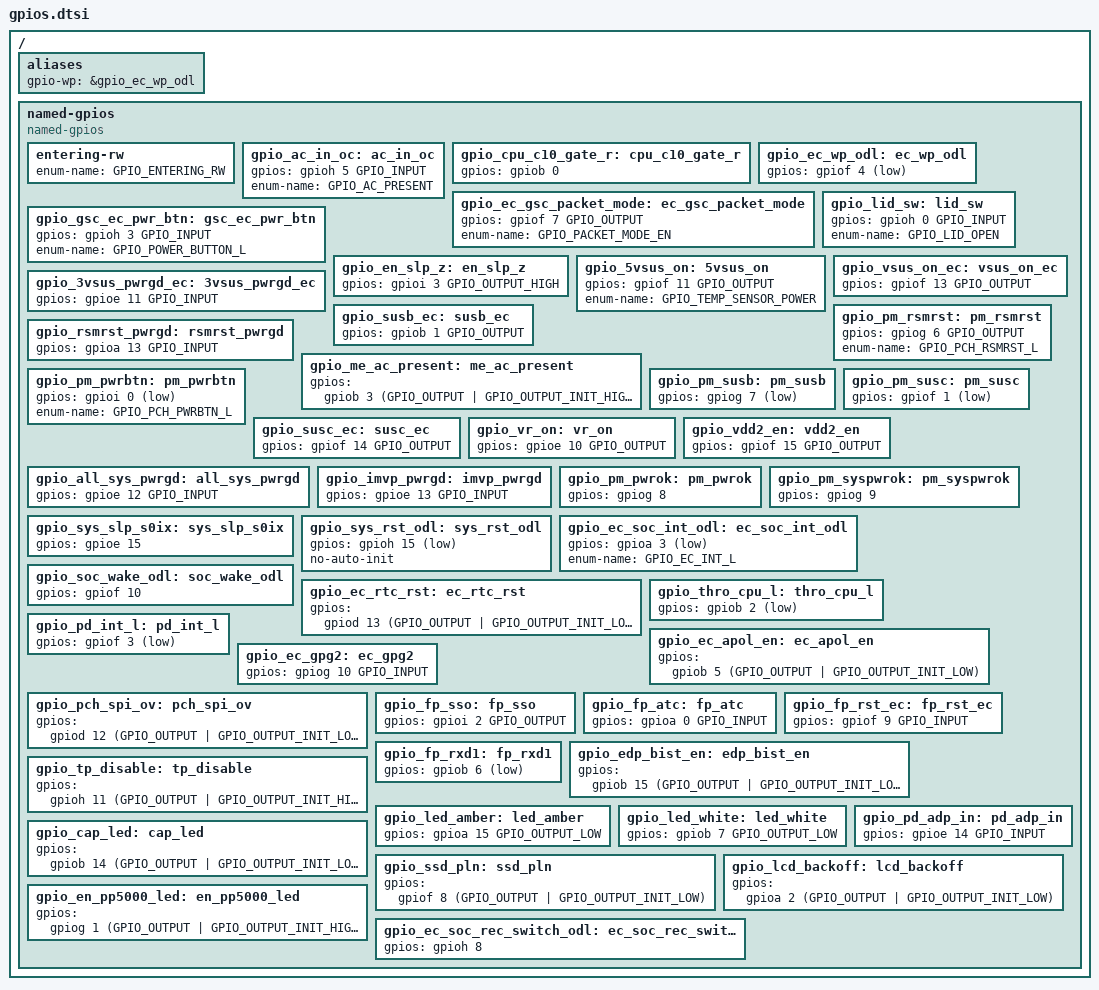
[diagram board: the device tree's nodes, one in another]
/* Copyright 2025 The ChromiumOS Authors
 * Use of this source code is governed by a BSD-style license that can be
 * found in the LICENSE file.
 */

/ {
	aliases {
		gpio-wp = &gpio_ec_wp_odl;
	};

	named-gpios {
		compatible = "named-gpios";

		/* unimplemented GPIOs */
		entering-rw {
			enum-name = "GPIO_ENTERING_RW";
		};

		/* AC_IN_OC#_EC */
		gpio_ac_in_oc: ac_in_oc {
			gpios = <&gpioh 5 GPIO_INPUT>;
			enum-name = "GPIO_AC_PRESENT";
		};
		/* CPU_C10_GATE# */
		gpio_cpu_c10_gate_r: cpu_c10_gate_r {
			gpios = <&gpiob 0 (GPIO_INPUT | GPIO_VOLTAGE_1P8)>;
		};
		/* EC_WP_ODL */
		gpio_ec_wp_odl: ec_wp_odl {
			gpios = <&gpiof 4 (GPIO_INPUT | GPIO_ACTIVE_LOW)>;
		};
		/* EC_GSC_PACKET_MODE */
		gpio_ec_gsc_packet_mode: ec_gsc_packet_mode {
			gpios = <&gpiof 7 GPIO_OUTPUT>;
			enum-name = "GPIO_PACKET_MODE_EN";
		};
		/* PWR_SW# */
		gpio_gsc_ec_pwr_btn: gsc_ec_pwr_btn {
			gpios = <&gpioh 3 GPIO_INPUT>;
			enum-name = "GPIO_POWER_BUTTON_L";
		};
		/* LID_SW# */
		gpio_lid_sw: lid_sw {
			gpios = <&gpioh 0 GPIO_INPUT>;
			enum-name = "GPIO_LID_OPEN";
		};

		/* PS_ON_EC slp_z */
		gpio_en_slp_z: en_slp_z {
			gpios = <&gpioi 3 GPIO_OUTPUT_HIGH>;
		};
		/* 5VSUS_ON */
		gpio_5vsus_on: 5vsus_on {
			gpios = <&gpiof 11 GPIO_OUTPUT>;
			enum-name = "GPIO_TEMP_SENSOR_POWER";
		};
		/* VSUS_ON_EC */
		gpio_vsus_on_ec: vsus_on_ec {
			gpios = <&gpiof 13 GPIO_OUTPUT>;
		};
		/* 3VSUS_PWRGD_EC */
		gpio_3vsus_pwrgd_ec: 3vsus_pwrgd_ec {
			gpios = <&gpioe 11 GPIO_INPUT>;
		};
		/* SUSB_EC# */
		gpio_susb_ec: susb_ec {
			gpios = <&gpiob 1 GPIO_OUTPUT>;
		};
		/* PM_RSMRST# */
		gpio_pm_rsmrst: pm_rsmrst {
			gpios = <&gpiog 6 GPIO_OUTPUT>;
			enum-name = "GPIO_PCH_RSMRST_L";
		};
		/* VCCPRIM_IO_PWRGD */
		gpio_rsmrst_pwrgd: rsmrst_pwrgd {
			gpios = <&gpioa 13 GPIO_INPUT>;
		};
		/* ME_AC_PRESENT */
		gpio_me_ac_present: me_ac_present{
			gpios = <&gpiob 3 (GPIO_OUTPUT | GPIO_OUTPUT_INIT_HIGH)>;
		};
		/* PM_PWRBTN# */
		gpio_pm_pwrbtn: pm_pwrbtn {
			gpios = <&gpioi 0 (GPIO_OUTPUT | GPIO_OPEN_DRAIN | GPIO_ACTIVE_LOW)>;
			enum-name = "GPIO_PCH_PWRBTN_L";
		};
		/* PM_SUSB#_EC SLP_S3 */
		gpio_pm_susb: pm_susb {
			gpios = <&gpiog 7 (GPIO_INPUT | GPIO_ACTIVE_LOW | GPIO_VOLTAGE_1P8)>;
		};
		/* PM_SUSC#_EC SLP_S4 */
		gpio_pm_susc: pm_susc {
			gpios = <&gpiof 1 (GPIO_INPUT | GPIO_ACTIVE_LOW | GPIO_VOLTAGE_1P8)>;
		};
		/* SUSC_EC# enable USBA */
		gpio_susc_ec: susc_ec {
			gpios = <&gpiof 14 GPIO_OUTPUT>;
		};
		/* VR_ON */
		gpio_vr_on: vr_on {
			gpios = <&gpioe 10 GPIO_OUTPUT>;
		};
		/* VDD2_EN */
		gpio_vdd2_en: vdd2_en {
			gpios = <&gpiof 15 GPIO_OUTPUT>;
		};
		/* ALL_SYSTEM_PWRGD */
		gpio_all_sys_pwrgd: all_sys_pwrgd {
			gpios = <&gpioe 12 GPIO_INPUT>;
		};
		/* IMVP9.3_PWRGD */
		gpio_imvp_pwrgd: imvp_pwrgd {
			gpios = <&gpioe 13 GPIO_INPUT>;
		};
		/* PM_PWROK */
		gpio_pm_pwrok: pm_pwrok {
			gpios = <&gpiog 8 (GPIO_OUTPUT | GPIO_ACTIVE_HIGH | GPIO_OUTPUT_INIT_LOW)>;
		};
		/* PM_SYSPWROK */
		gpio_pm_syspwrok: pm_syspwrok {
			gpios = <&gpiog 9 (GPIO_OUTPUT | GPIO_ACTIVE_HIGH | GPIO_OUTPUT_INIT_LOW)>;
		};
		/* SYS_SLP_S0IX# */
		gpio_sys_slp_s0ix: sys_slp_s0ix {
			gpios = <&gpioe 15 (GPIO_INPUT | GPIO_VOLTAGE_1P8)>;
		};
		/* PM_SYSRST_R#, ROM_ID */
		gpio_sys_rst_odl: sys_rst_odl {
			gpios = <&gpioh 15 (GPIO_OUTPUT | GPIO_OPEN_DRAIN | GPIO_ACTIVE_LOW | GPIO_OUTPUT_INIT_HIGH)>;
			no-auto-init;
		};
		/* ESPI_ALERT0#_EC, EC_SOC_INT_ODL */
		gpio_ec_soc_int_odl: ec_soc_int_odl {
			gpios = <&gpioa 3 (GPIO_OUTPUT | GPIO_OPEN_DRAIN | GPIO_ACTIVE_LOW | GPIO_OUTPUT_INIT_HIGH)>;
			enum-name = "GPIO_EC_INT_L";
		};
		/* SOC_WAKE#, use EC_MSPI_CS instead.
		 * Not to be marked as active low, the lpc_update_wake() already
		 * has the logic to invert the value.
		 */
		gpio_soc_wake_odl: soc_wake_odl {
			gpios = <&gpiof 10 (GPIO_OUTPUT | GPIO_OPEN_DRAIN | GPIO_OUTPUT_INIT_HIGH)>;
		};
		/* EC_RTC_RST */
		gpio_ec_rtc_rst: ec_rtc_rst {
			gpios = <&gpiod 13 (GPIO_OUTPUT | GPIO_OUTPUT_INIT_LOW)>;
		};
		/* THRO_CPU# */
		gpio_thro_cpu_l: thro_cpu_l {
			gpios = <&gpiob 2 (GPIO_INPUT | GPIO_ACTIVE_LOW)>;
		};

		/* PD_INT1# */
		gpio_pd_int_l: pd_int_l {
			gpios = <&gpiof 3 (GPIO_INPUT | GPIO_ACTIVE_LOW)>;
		};
		/* EC_APOL_EN */
		gpio_ec_apol_en: ec_apol_en {
			gpios = <&gpiob 5 (GPIO_OUTPUT | GPIO_OUTPUT_INIT_LOW)>;
		};
		/* EC_GPG2 bios_sel*/
		gpio_ec_gpg2: ec_gpg2 {
			gpios = <&gpiog 10 GPIO_INPUT>;
		};
		/* PCH_SPI_OV, cpu straps pin */
		gpio_pch_spi_ov: pch_spi_ov {
			gpios = <&gpiod 12 (GPIO_OUTPUT | GPIO_OUTPUT_INIT_LOW)>;
		};
		/* FP_SSO */
		gpio_fp_sso: fp_sso {
			gpios = <&gpioi 2 GPIO_OUTPUT>;
		};
		/* FP_ATC */
		gpio_fp_atc: fp_atc {
			gpios = <&gpioa 0 GPIO_INPUT>;
		};
		/* FP_RST_EC GPIO089*/
		gpio_fp_rst_ec: fp_rst_ec {
			gpios = <&gpiof 9 GPIO_INPUT>;
		};

		gpio_fp_rxd1: fp_rxd1 {
			gpios = <&gpiob 6 (GPIO_OUTPUT | GPIO_ACTIVE_LOW | GPIO_OUTPUT_INIT_HIGH)>;
		};

		/* EDP_BIST_EN */
		gpio_edp_bist_en: edp_bist_en {
			gpios = <&gpiob 15 (GPIO_OUTPUT | GPIO_OUTPUT_INIT_LOW)>;
		};
		/* TP_Disable */
		gpio_tp_disable: tp_disable {
			gpios = <&gpioh 11 (GPIO_OUTPUT | GPIO_OUTPUT_INIT_HIGH)>;
		};
		/* Amber LED */
		gpio_led_amber: led_amber {
			gpios = <&gpioa 15 GPIO_OUTPUT_LOW>;
		};
		/* White LED */
		gpio_led_white: led_white {
			gpios = <&gpiob 7 GPIO_OUTPUT_LOW>;
		};
		/* CAP_LED */
		gpio_cap_led: cap_led {
			gpios = <&gpiob 14 (GPIO_OUTPUT | GPIO_OUTPUT_INIT_LOW)>;
		};
		/* PD_ADP_IN_3VA high--PD SINK */
		gpio_pd_adp_in: pd_adp_in {
			gpios = <&gpioe 14 GPIO_INPUT>;
		};
		/* SSD_PLN */
		gpio_ssd_pln: ssd_pln {
			gpios = <&gpiof 8 (GPIO_OUTPUT | GPIO_OUTPUT_INIT_LOW)>;
		};
		/* LCD_BACKOFF# */
		gpio_lcd_backoff: lcd_backoff {
			gpios = <&gpioa 2 (GPIO_OUTPUT | GPIO_OUTPUT_INIT_LOW)>;
		};
		/* EN_PP5000_LED_X */
		gpio_en_pp5000_led: en_pp5000_led {
			gpios = <&gpiog 1 (GPIO_OUTPUT | GPIO_OUTPUT_INIT_HIGH)>;
		};
		/* EC_SOC_REC_SWITCH_ODL */
		gpio_ec_soc_rec_switch_odl: ec_soc_rec_switch_odl {
			gpios = <&gpioh 8 (GPIO_OUTPUT | GPIO_OPEN_DRAIN | GPIO_ACTIVE_HIGH | GPIO_OUTPUT_INIT_LOW)>;
		};
	};
};
